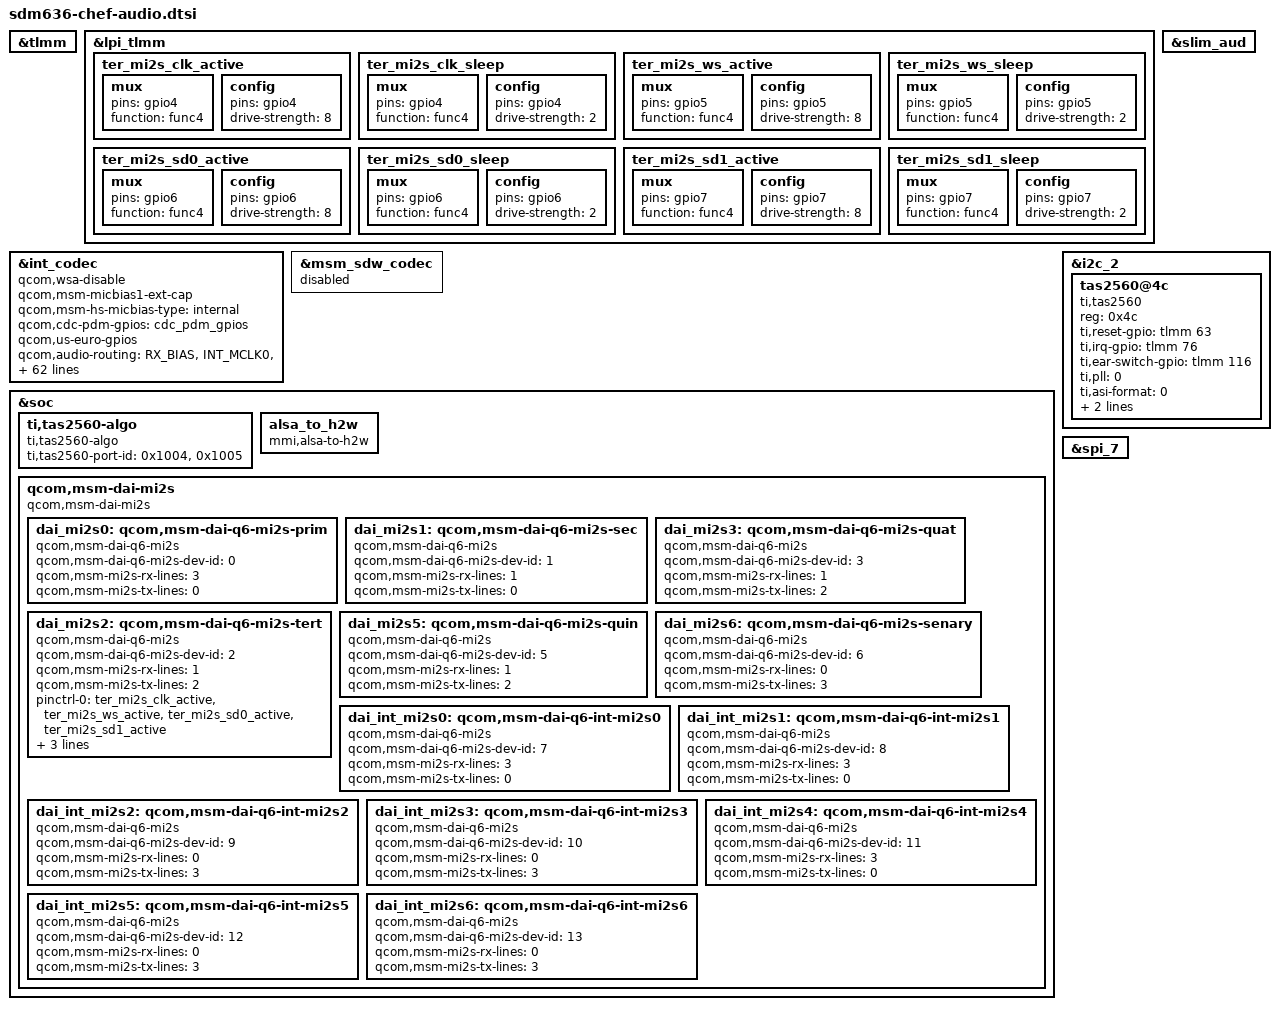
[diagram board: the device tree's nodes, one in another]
/* Copyright (c) 2017, Motorola Mobility Inc. All rights reserved.
 *
 * This program is free software; you can redistribute it and/or modify
 * it under the terms of the GNU General Public License version 2 and
 * only version 2 as published by the Free Software Foundation.
 *
 * This program is distributed in the hope that it will be useful,
 * but WITHOUT ANY WARRANTY; without even the implied warranty of
 * MERCHANTABILITY or FITNESS FOR A PARTICULAR PURPOSE.  See the
 * GNU General Public License for more details.
 */

&tlmm {
	/delete-node/ cs35l35_reset_default;
	/delete-node/ cs35l35_irq_default;
	/delete-node/ marley_irq_default;
	/delete-node/ marley_reset_default;
};


&lpi_tlmm {
	ter_mi2s_clk_active: ter_mi2s_clk_active {
		mux {
			pins = "gpio4";
			function = "func4";
		};

		config {
			pins = "gpio4";
			drive-strength = <8>;
		};
	};

	ter_mi2s_clk_sleep: ter_mi2s_clk_sleep {
		mux {
			pins = "gpio4";
			function = "func4";
		};

		config {
			pins = "gpio4";
			drive-strength = <2>;
		};
	};

	ter_mi2s_ws_active: ter_mi2s_ws_active {
		mux {
			pins = "gpio5";
			function = "func4";
		};

		config {
			pins = "gpio5";
			drive-strength = <8>;
		};
	};

	ter_mi2s_ws_sleep: ter_mi2s_ws_sleep {
		mux {
			pins = "gpio5";
			function = "func4";
		};

		config {
			pins = "gpio5";
			drive-strength = <2>;
		};
	};

	ter_mi2s_sd0_active: ter_mi2s_sd0_active {
		mux {
			pins = "gpio6";
			function = "func4";
		};

		config {
			pins = "gpio6";
			drive-strength = <8>;
		};
	};

	ter_mi2s_sd0_sleep: ter_mi2s_sd0_sleep {
		mux {
			pins = "gpio6";
			function = "func4";
		};

		config {
			pins = "gpio6";
			drive-strength = <2>;
		};
	};

	ter_mi2s_sd1_active: ter_mi2s_sd1_active {
		mux {
			pins = "gpio7";
			function = "func4";
		};

		config {
			pins = "gpio7";
			drive-strength = <8>;
		};
	};

	ter_mi2s_sd1_sleep: ter_mi2s_sd1_sleep {
		mux {
			pins = "gpio7";
			function = "func4";
		};

		config {
			pins = "gpio7";
			drive-strength = <2>;
		};
	};
};

&int_codec {
        status = "okay";
        /delete-property/ asoc-platform;
        /delete-property/ asoc-platform-names;
        qcom,wsa-disable;
        qcom,msm-micbias1-ext-cap;
        qcom,msm-hs-micbias-type = "internal";
        qcom,cdc-pdm-gpios = <&cdc_pdm_gpios>;
        qcom,us-euro-gpios;
        qcom,audio-routing =
                "RX_BIAS", "INT_MCLK0",
                "SPK_RX_BIAS", "INT_MCLK0",
                "INT_LDO_H", "INT_MCLK0",
                "RX_I2S_CLK", "INT_MCLK0",
                "TX_I2S_CLK", "INT_MCLK0",
                "MIC BIAS External", "Handset Mic",
                "MIC BIAS Internal2", "Headset Mic",
                "MIC BIAS External", "Secondary Mic",
                "AMIC1", "MIC BIAS External",
                "AMIC2", "MIC BIAS Internal2",
                "AMIC3", "MIC BIAS External",
                "PDM_IN_RX1", "PDM_OUT_RX1",
                "PDM_IN_RX2", "PDM_OUT_RX2",
                "PDM_IN_RX3", "PDM_OUT_RX3",
                "ADC1_IN", "ADC1_OUT",
                "ADC2_IN", "ADC2_OUT",
                "ADC3_IN", "ADC3_OUT";
                asoc-platform = <&pcm0>, <&pcm1>, <&pcm2>, <&voip>, <&voice>,
                                <&loopback>, <&compress>, <&hostless>,
                                <&afe>, <&lsm>, <&routing>, <&compr>,
                                <&pcm_noirq>;
                asoc-platform-names = "msm-pcm-dsp.0", "msm-pcm-dsp.1",
                                "msm-pcm-dsp.2", "msm-voip-dsp",
                                "msm-pcm-voice", "msm-pcm-loopback",
                                "msm-compress-dsp", "msm-pcm-hostless",
                                "msm-pcm-afe", "msm-lsm-client",
                                "msm-pcm-routing", "msm-compr-dsp",
                                "msm-pcm-dsp-noirq";
		asoc-cpu = <&dai_dp>, <&dai_mi2s0>,
                                <&dai_mi2s1>,
                                <&dai_mi2s2>, <&dai_mi2s3>,
                                <&dai_int_mi2s0>, <&dai_int_mi2s1>,
                                <&dai_int_mi2s2>, <&dai_int_mi2s3>,
                                <&dai_int_mi2s4>, <&dai_int_mi2s5>,
                                <&dai_pri_auxpcm>, <&dai_sec_auxpcm>,
                                <&dai_tert_auxpcm>, <&dai_quat_auxpcm>,
                                <&afe_pcm_rx>, <&afe_pcm_tx>, <&afe_proxy_rx>,
                                <&afe_proxy_tx>, <&incall_record_rx>,
                                <&incall_record_tx>, <&incall_music_rx>,
                                <&incall_music_2_rx>, <&sb_7_rx>, <&sb_7_tx>,
                                <&sb_8_tx>, <&sb_8_rx>,
                                <&usb_audio_rx>, <&usb_audio_tx>,
                                <&dai_pri_tdm_rx_0>, <&dai_pri_tdm_tx_0>,
                                <&dai_sec_tdm_rx_0>, <&dai_sec_tdm_tx_0>,
                                <&dai_tert_tdm_rx_0>, <&dai_tert_tdm_tx_0>,
                                <&dai_quat_tdm_rx_0>, <&dai_quat_tdm_tx_0>;
                asoc-cpu-names = "msm-dai-q6-dp.24608", "msm-dai-q6-mi2s.0",
                                "msm-dai-q6-mi2s.1",
                                "msm-dai-q6-mi2s.2", "msm-dai-q6-mi2s.3",
                                "msm-dai-q6-mi2s.7", "msm-dai-q6-mi2s.8",
                                "msm-dai-q6-mi2s.9", "msm-dai-q6-mi2s.10",
                                "msm-dai-q6-mi2s.11", "msm-dai-q6-mi2s.12",
                                "msm-dai-q6-auxpcm.1", "msm-dai-q6-auxpcm.2",
                                "msm-dai-q6-auxpcm.3", "msm-dai-q6-auxpcm.4",
                                "msm-dai-q6-dev.224", "msm-dai-q6-dev.225",
                                "msm-dai-q6-dev.241", "msm-dai-q6-dev.240",
                                "msm-dai-q6-dev.32771", "msm-dai-q6-dev.32772",
                                "msm-dai-q6-dev.32773", "msm-dai-q6-dev.32770",
                                "msm-dai-q6-dev.16398", "msm-dai-q6-dev.16399",
                                "msm-dai-q6-dev.16401", "msm-dai-q6-dev.16400",
                                "msm-dai-q6-dev.28672", "msm-dai-q6-dev.28673",
                                "msm-dai-q6-tdm.36864", "msm-dai-q6-tdm.36865",
                                "msm-dai-q6-tdm.36880", "msm-dai-q6-tdm.36881",
                                "msm-dai-q6-tdm.36896", "msm-dai-q6-tdm.36897",
                                "msm-dai-q6-tdm.36912", "msm-dai-q6-tdm.36913";
                asoc-codec = <&stub_codec>, <&msm_digital_codec>,
                                <&pmic_analog_codec>, <&msm_sdw_codec>,
                                <&ext_disp_audio_codec>;
                asoc-codec-names = "msm-stub-codec.1", "msm-dig-codec",
                                        "analog-codec", "msm_sdw_codec",
                                        "msm-ext-disp-audio-codec-rx";
};

&msm_sdw_codec {
        status = "disabled";
};

&soc {
	ti,tas2560-algo {
		compatible = "ti,tas2560-algo";
		ti,tas2560-port-id = <0x1004>, <0x1005>;
	};

	alsa_to_h2w {
		compatible = "mmi,alsa-to-h2w";
	};


	/delete-node/ ospl;
	/delete-node/ qcom,wcd-dsp-mgr;
	/delete-node/ qcom,wcd-dsp-glink;
	/delete-node/ sound-9335;
	/delete-node/ sound-tavil;
	/delete-node/ sound-madera;

	qcom,msm-dai-mi2s {
		compatible = "qcom,msm-dai-mi2s";
		status = "okay";
                dai_mi2s0: qcom,msm-dai-q6-mi2s-prim {
		status = "okay";
                        compatible = "qcom,msm-dai-q6-mi2s";
                        qcom,msm-dai-q6-mi2s-dev-id = <0>;
                        qcom,msm-mi2s-rx-lines = <3>;
                        qcom,msm-mi2s-tx-lines = <0>;
                };

                dai_mi2s1: qcom,msm-dai-q6-mi2s-sec {
		status = "okay";
                        compatible = "qcom,msm-dai-q6-mi2s";
                        qcom,msm-dai-q6-mi2s-dev-id = <1>;
                        qcom,msm-mi2s-rx-lines = <1>;
                        qcom,msm-mi2s-tx-lines = <0>;
                };

                dai_mi2s3: qcom,msm-dai-q6-mi2s-quat {
		status = "okay";
                        compatible = "qcom,msm-dai-q6-mi2s";
                        qcom,msm-dai-q6-mi2s-dev-id = <3>;
                        qcom,msm-mi2s-rx-lines = <1>;
                        qcom,msm-mi2s-tx-lines = <2>;
                };

                dai_mi2s2: qcom,msm-dai-q6-mi2s-tert {
		status = "okay";
                        compatible = "qcom,msm-dai-q6-mi2s";
                        qcom,msm-dai-q6-mi2s-dev-id = <2>;
                        qcom,msm-mi2s-rx-lines = <1>;
                        qcom,msm-mi2s-tx-lines = <2>;
			pinctrl-names = "default","sleep";
			pinctrl-0 = <&ter_mi2s_clk_active &ter_mi2s_ws_active
				&ter_mi2s_sd0_active &ter_mi2s_sd1_active>;
			pinctrl-1 = <&ter_mi2s_clk_sleep &ter_mi2s_ws_sleep
				&ter_mi2s_sd0_sleep &ter_mi2s_sd1_sleep>;
		};

                dai_mi2s5: qcom,msm-dai-q6-mi2s-quin {
		status = "okay";
                        compatible = "qcom,msm-dai-q6-mi2s";
                        qcom,msm-dai-q6-mi2s-dev-id = <5>;
                        qcom,msm-mi2s-rx-lines = <1>;
                        qcom,msm-mi2s-tx-lines = <2>;
                };

                dai_mi2s6: qcom,msm-dai-q6-mi2s-senary {
		status = "okay";
                        compatible = "qcom,msm-dai-q6-mi2s";
                        qcom,msm-dai-q6-mi2s-dev-id = <6>;
                        qcom,msm-mi2s-rx-lines = <0>;
                        qcom,msm-mi2s-tx-lines = <3>;
                };


		dai_int_mi2s0: qcom,msm-dai-q6-int-mi2s0 {
			status = "okay";
                        compatible = "qcom,msm-dai-q6-mi2s";
                        qcom,msm-dai-q6-mi2s-dev-id = <7>;
                        qcom,msm-mi2s-rx-lines = <3>;
                        qcom,msm-mi2s-tx-lines = <0>;
                };

                dai_int_mi2s1: qcom,msm-dai-q6-int-mi2s1 {
			status = "okay";
                        compatible = "qcom,msm-dai-q6-mi2s";
                        qcom,msm-dai-q6-mi2s-dev-id = <8>;
                        qcom,msm-mi2s-rx-lines = <3>;
                        qcom,msm-mi2s-tx-lines = <0>;
                };

                dai_int_mi2s2: qcom,msm-dai-q6-int-mi2s2 {
			status = "okay";
                        compatible = "qcom,msm-dai-q6-mi2s";
                        qcom,msm-dai-q6-mi2s-dev-id = <9>;
                        qcom,msm-mi2s-rx-lines = <0>;
                        qcom,msm-mi2s-tx-lines = <3>;
                };

                dai_int_mi2s3: qcom,msm-dai-q6-int-mi2s3 {
			status = "okay";
                        compatible = "qcom,msm-dai-q6-mi2s";
                        qcom,msm-dai-q6-mi2s-dev-id = <10>;
                        qcom,msm-mi2s-rx-lines = <0>;
                        qcom,msm-mi2s-tx-lines = <3>;
                };

                dai_int_mi2s4: qcom,msm-dai-q6-int-mi2s4 {
			status = "okay";
                        compatible = "qcom,msm-dai-q6-mi2s";
                        qcom,msm-dai-q6-mi2s-dev-id = <11>;
                        qcom,msm-mi2s-rx-lines = <3>;
                        qcom,msm-mi2s-tx-lines = <0>;
                };

                dai_int_mi2s5: qcom,msm-dai-q6-int-mi2s5 {
			status = "okay";
                        compatible = "qcom,msm-dai-q6-mi2s";
                        qcom,msm-dai-q6-mi2s-dev-id = <12>;
                        qcom,msm-mi2s-rx-lines = <0>;
                        qcom,msm-mi2s-tx-lines = <3>;
                };

                dai_int_mi2s6: qcom,msm-dai-q6-int-mi2s6 {
			status = "okay";
                        compatible = "qcom,msm-dai-q6-mi2s";
                        qcom,msm-dai-q6-mi2s-dev-id = <13>;
                        qcom,msm-mi2s-rx-lines = <0>;
                        qcom,msm-mi2s-tx-lines = <3>;
                };

	};
};	

&slim_aud {
	/delete-node/ tasha_codec;
	/delete-node/ tavil_codec;
	/delete-node/ madera-codec;
};

&i2c_2 {
	status = "okay";
	/delete-node/ cs35l35@40;
	tas2560@4c {
		compatible = "ti,tas2560";
		reg = <0x4c>;
		ti,reset-gpio = <&tlmm 63 0>;
		ti,irq-gpio = <&tlmm 76 0>;
		ti,ear-switch-gpio = <&tlmm 116 0>;
		ti,pll = <0>; /* refer to tas2560.h for more details */
		ti,asi-format = <0>; /* 0, i2S; 1, DSP;  */
		ti,load = <1>; /* 0, 8Ohm; 1, 6Ohm; 2, 4Ohm */
		ti,ppg = <110>; /*attenuation,0(-110db)~110(0db) */
		status = "ok";
        };
};

&spi_7 {
	/delete-node/ cs47l35;
};
